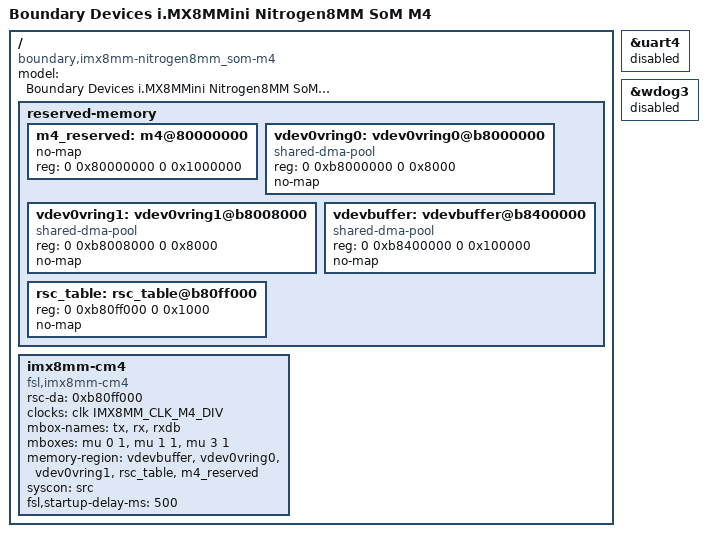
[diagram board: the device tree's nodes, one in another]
// SPDX-License-Identifier: (GPL-2.0+ OR MIT)
/*
 * Copyright 2018 Boundary Devices
 */

#include "imx8mm-nitrogen8mm_som.dts"

/ {
	model = "Boundary Devices i.MX8MMini Nitrogen8MM SoM M4";
	compatible = "boundary,imx8mm-nitrogen8mm_som-m4", "fsl,imx8mm";

	reserved-memory {
		#address-cells = <2>;
		#size-cells = <2>;
		ranges;

		m4_reserved: m4@80000000 {
			no-map;
			reg = <0 0x80000000 0 0x1000000>;
		};

		vdev0vring0: vdev0vring0@b8000000 {
			compatible = "shared-dma-pool";
			reg = <0 0xb8000000 0 0x8000>;
			no-map;
		};

		vdev0vring1: vdev0vring1@b8008000 {
			compatible = "shared-dma-pool";
			reg = <0 0xb8008000 0 0x8000>;
			no-map;
		};

		vdevbuffer: vdevbuffer@b8400000 {
			compatible = "shared-dma-pool";
			reg = <0 0xb8400000 0 0x100000>;
			no-map;
		};

		rsc_table: rsc_table@b80ff000 {
			reg = <0 0xb80ff000 0 0x1000>;
			no-map;
		};
	};

	imx8mm-cm4 {
		compatible = "fsl,imx8mm-cm4";
		rsc-da = <0xb80ff000>;
		clocks = <&clk IMX8MM_CLK_M4_DIV>;
		mbox-names = "tx", "rx", "rxdb";
		mboxes = <&mu 0 1
			  &mu 1 1
			  &mu 3 1>;
		memory-region = <&vdevbuffer>, <&vdev0vring0>, <&vdev0vring1>,
				<&rsc_table>, <&m4_reserved>;
		syscon = <&src>;
		fsl,startup-delay-ms = <500>;
	};
};

&uart4 {
	status = "disabled";
};

&wdog3 {
	status = "disabled";
};
